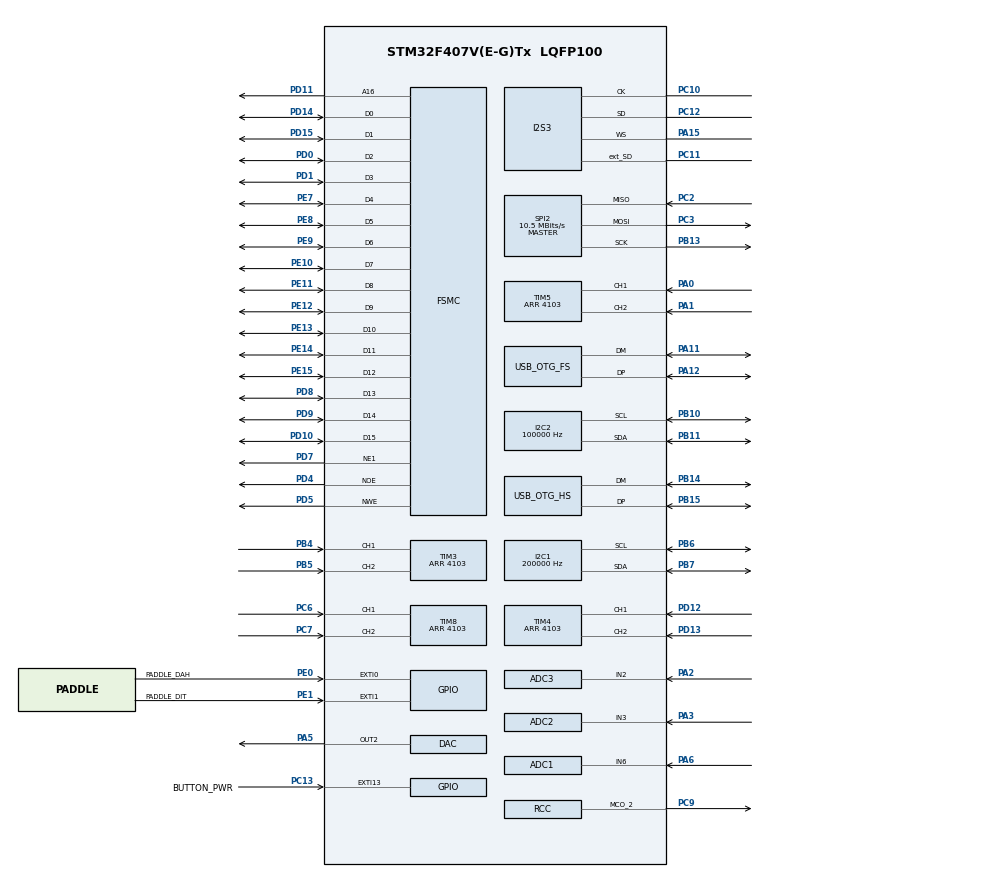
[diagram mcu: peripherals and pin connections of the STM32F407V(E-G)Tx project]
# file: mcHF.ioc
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ADC1.Channel-0\#ChannelRegularConversion=ADC_CHANNEL_6
ADC1.ClockPrescaler=ADC_CLOCK_SYNC_PCLK_DIV8
ADC1.ContinuousConvMode=ENABLE
ADC1.EOCSelection=ADC_EOC_SEQ_CONV
ADC1.NbrOfConversionFlag=1
ADC1.Rank-0\#ChannelRegularConversion=1
ADC1.SamplingTime-0\#ChannelRegularConversion=ADC_SAMPLETIME_3CYCLES
ADC1.master=1
ADC2.Channel-5\#ChannelRegularConversion=ADC_CHANNEL_3
ADC2.ClockPrescaler=ADC_CLOCK_SYNC_PCLK_DIV8
ADC2.ContinuousConvMode=ENABLE
ADC2.EOCSelection=ADC_EOC_SEQ_CONV
ADC2.NbrOfConversionFlag=1
ADC2.Rank-5\#ChannelRegularConversion=1
ADC2.SamplingTime-5\#ChannelRegularConversion=ADC_SAMPLETIME_3CYCLES
ADC3.Channel-5\#ChannelRegularConversion=ADC_CHANNEL_2
ADC3.ClockPrescaler=ADC_CLOCK_SYNC_PCLK_DIV8
ADC3.ContinuousConvMode=ENABLE
ADC3.EOCSelection=ADC_EOC_SEQ_CONV
ADC3.NbrOfConversionFlag=1
ADC3.Rank-5\#ChannelRegularConversion=1
ADC3.SamplingTime-5\#ChannelRegularConversion=ADC_SAMPLETIME_3CYCLES
Dma.I2S3_EXT_RX.2.Direction=DMA_PERIPH_TO_MEMORY
Dma.I2S3_EXT_RX.2.FIFOMode=DMA_FIFOMODE_ENABLE
Dma.I2S3_EXT_RX.2.FIFOThreshold=DMA_FIFO_THRESHOLD_FULL
Dma.I2S3_EXT_RX.2.Instance=DMA1_Stream2
Dma.I2S3_EXT_RX.2.MemBurst=DMA_MBURST_INC4
Dma.I2S3_EXT_RX.2.MemDataAlignment=DMA_MDATAALIGN_HALFWORD
Dma.I2S3_EXT_RX.2.MemInc=DMA_MINC_ENABLE
Dma.I2S3_EXT_RX.2.Mode=DMA_CIRCULAR
Dma.I2S3_EXT_RX.2.PeriphBurst=DMA_PBURST_SINGLE
Dma.I2S3_EXT_RX.2.PeriphDataAlignment=DMA_PDATAALIGN_HALFWORD
Dma.I2S3_EXT_RX.2.PeriphInc=DMA_PINC_DISABLE
Dma.I2S3_EXT_RX.2.Priority=DMA_PRIORITY_HIGH
Dma.Request0=SPI2_TX
Dma.Request1=SPI3_TX
Dma.Request2=I2S3_EXT_RX
Dma.SPI2_TX.0.Direction=DMA_MEMORY_TO_PERIPH
Dma.SPI2_TX.0.FIFOMode=DMA_FIFOMODE_DISABLE
Dma.SPI2_TX.0.Instance=DMA1_Stream4
Dma.SPI2_TX.0.MemDataAlignment=DMA_MDATAALIGN_BYTE
Dma.SPI2_TX.0.MemInc=DMA_MINC_ENABLE
Dma.SPI2_TX.0.Mode=DMA_NORMAL
Dma.SPI2_TX.0.PeriphDataAlignment=DMA_PDATAALIGN_BYTE
Dma.SPI2_TX.0.PeriphInc=DMA_PINC_DISABLE
Dma.SPI2_TX.0.Priority=DMA_PRIORITY_LOW
Dma.SPI3_TX.1.Direction=DMA_MEMORY_TO_PERIPH
Dma.SPI3_TX.1.FIFOMode=DMA_FIFOMODE_ENABLE
Dma.SPI3_TX.1.FIFOThreshold=DMA_FIFO_THRESHOLD_FULL
Dma.SPI3_TX.1.Instance=DMA1_Stream5
Dma.SPI3_TX.1.MemBurst=DMA_MBURST_SINGLE
Dma.SPI3_TX.1.MemDataAlignment=DMA_MDATAALIGN_HALFWORD
Dma.SPI3_TX.1.MemInc=DMA_MINC_ENABLE
Dma.SPI3_TX.1.Mode=DMA_CIRCULAR
Dma.SPI3_TX.1.PeriphBurst=DMA_PBURST_SINGLE
Dma.SPI3_TX.1.PeriphDataAlignment=DMA_PDATAALIGN_HALFWORD
Dma.SPI3_TX.1.PeriphInc=DMA_PINC_DISABLE
Dma.SPI3_TX.1.Priority=DMA_PRIORITY_HIGH
FSMC.AddressSetupTime1=6
FSMC.BusTurnAroundDuration1=0
FSMC.DataSetupTime1=15
I2C1.ClockSpeed=200000
I2C1.DutyCycle=I2C_DUTYCYCLE_16_9
I2C1.I2C_Mode=I2C_Fast
I2C1.OwnAddress=0x33
I2C2.ClockSpeed=100000
I2C2.DutyCycle=I2C_DUTYCYCLE_16_9
I2C2.I2C_Mode=I2C_Fast
I2C2.OwnAddress=0x33
I2S3.AudioFreq=I2S_AUDIOFREQ_96K
I2S3.ErrorAudioFreq=0.0 %
I2S3.FullDuplexMode=I2S_FULLDUPLEXMODE_ENABLE
I2S3.Instance=SPI$Index
I2S3.RealAudioFreq=96.0 KHz
I2S3.VirtualMode=I2S_MODE_MASTER
Mcu.Family=STM32F4
Mcu.Name=STM32F407V(E-G)Tx
Mcu.Package=LQFP100
NVIC.DMA1_Stream2_IRQn=true\:2\:0\:true\:false\:true\:true
NVIC.DMA1_Stream4_IRQn=true\:14\:0\:true\:false\:true\:true
NVIC.DMA1_Stream5_IRQn=true\:14\:0\:true\:false\:true\:true
NVIC.EXTI0_IRQn=true\:14\:0\:true\:false\:true\:true
NVIC.EXTI15_10_IRQn=true\:14\:0\:true\:false\:true\:true
NVIC.EXTI1_IRQn=true\:14\:0\:true\:false\:true\:true
NVIC.OTG_FS_IRQn=true\:1\:0\:true\:false\:true\:true
NVIC.OTG_HS_IRQn=true\:14\:0\:true\:false\:true\:true
NVIC.PriorityGroup=NVIC_PRIORITYGROUP_4
PA0-WKUP.GPIO_PuPd=GPIO_PULLUP
PA0-WKUP.Signal=S_TIM5_CH1
PA1.GPIO_PuPd=GPIO_PULLUP
PA1.Signal=S_TIM5_CH2
PA11.Mode=Device_Only
PA11.Signal=USB_OTG_FS_DM
PA12.Mode=Device_Only
PA12.Signal=USB_OTG_FS_DP
PA13.Mode=Serial_Wire
PA13.Signal=SYS_JTMS-SWDIO
PA14.Mode=Serial_Wire
PA14.Signal=SYS_JTCK-SWCLK
PA15.Mode=Full_Duplex_Master
PA15.Signal=I2S3_WS
PA2.Signal=ADCx_IN2
PA3.Signal=ADCx_IN3
PA5.Signal=COMP_DAC2_group
PA6.Signal=ADCx_IN6
PB10.Mode=I2C
PB10.Signal=I2C2_SCL
PB11.Mode=I2C
PB11.Signal=I2C2_SDA
PB13.Mode=Full_Duplex_Master
PB13.Signal=SPI2_SCK
PB14.Mode=Host_FS
PB14.Signal=USB_OTG_HS_DM
PB15.Mode=Host_FS
PB15.Signal=USB_OTG_HS_DP
PB4.GPIO_PuPd=GPIO_PULLUP
PB4.Signal=S_TIM3_CH1
PB5.GPIO_PuPd=GPIO_PULLUP
PB5.Signal=S_TIM3_CH2
PB6.Mode=I2C
PB6.Signal=I2C1_SCL
PB7.Mode=I2C
PB7.Signal=I2C1_SDA
PC10.Mode=Full_Duplex_Master
PC10.Signal=I2S3_CK
PC11.Mode=Full_Duplex_Master
PC11.Signal=I2S3_ext_SD
PC12.Mode=Full_Duplex_Master
PC12.Signal=I2S3_SD
PC13-ANTI_TAMP.GPIO_Label=BUTTON_PWR
PC13-ANTI_TAMP.GPIO_ModeDefaultEXTI=GPIO_MODE_IT_FALLING
PC13-ANTI_TAMP.GPIO_PuPd=GPIO_PULLUP
PC13-ANTI_TAMP.Signal=GPXTI13
PC14-OSC32_IN.Mode=LSE-External-Oscillator
PC14-OSC32_IN.Signal=RCC_OSC32_IN
PC15-OSC32_OUT.Mode=LSE-External-Oscillator
PC15-OSC32_OUT.Signal=RCC_OSC32_OUT
PC2.Mode=Full_Duplex_Master
PC2.Signal=SPI2_MISO
PC3.Mode=Full_Duplex_Master
PC3.Signal=SPI2_MOSI
PC6.GPIO_PuPd=GPIO_PULLUP
PC6.Signal=S_TIM8_CH1
PC7.GPIO_PuPd=GPIO_PULLUP
PC7.Signal=S_TIM8_CH2
PC9.Mode=Clock-out-2
PC9.Signal=RCC_MCO_2
PD0.Mode=16b-d1
PD0.Signal=FSMC_D2
PD1.Mode=16b-d1
PD1.Signal=FSMC_D3
PD10.Mode=16b-d1
PD10.Signal=FSMC_D15
PD11.Mode=A16_1
PD11.Signal=FSMC_A16
PD12.GPIO_PuPd=GPIO_PULLUP
PD12.Signal=S_TIM4_CH1
PD13.GPIO_PuPd=GPIO_PULLUP
PD13.Signal=S_TIM4_CH2
PD14.Mode=16b-d1
PD14.Signal=FSMC_D0
PD15.Mode=16b-d1
PD15.Signal=FSMC_D1
PD4.Mode=Lcd1
PD4.Signal=FSMC_NOE
PD5.Mode=Lcd1
PD5.Signal=FSMC_NWE
PD7.Mode=NorPsramChipSelect1_1
PD7.Signal=FSMC_NE1
PD8.Mode=16b-d1
PD8.Signal=FSMC_D13
PD9.Mode=16b-d1
PD9.Signal=FSMC_D14
PE0.GPIO_Label=PADDLE_DAH
PE0.GPIO_ModeDefaultEXTI=GPIO_MODE_IT_FALLING
PE0.GPIO_PuPd=GPIO_PULLUP
PE0.Signal=GPXTI0
PE1.GPIO_Label=PADDLE_DIT
PE1.GPIO_ModeDefaultEXTI=GPIO_MODE_IT_FALLING
PE1.GPIO_PuPd=GPIO_PULLUP
PE1.Signal=GPXTI1
PE10.Mode=16b-d1
PE10.Signal=FSMC_D7
PE11.Mode=16b-d1
PE11.Signal=FSMC_D8
PE12.Mode=16b-d1
PE12.Signal=FSMC_D9
PE13.Mode=16b-d1
PE13.Signal=FSMC_D10
PE14.Mode=16b-d1
PE14.Signal=FSMC_D11
PE15.Mode=16b-d1
PE15.Signal=FSMC_D12
PE7.Mode=16b-d1
PE7.Signal=FSMC_D4
PE8.Mode=16b-d1
PE8.Signal=FSMC_D5
PE9.Mode=16b-d1
PE9.Signal=FSMC_D6
PH0-OSC_IN.Mode=HSE-External-Oscillator
PH0-OSC_IN.Signal=RCC_OSC_IN
PH1-OSC_OUT.Mode=HSE-External-Oscillator
PH1-OSC_OUT.Signal=RCC_OSC_OUT
ProjectManager.HeapSize=0x200
ProjectManager.StackSize=0x400
ProjectManager.TargetToolchain=Other Toolchains (GPDSC)
RCC.48MHZClocksFreq_Value=48000000
RCC.AHBFreq_Value=168000000
RCC.APB1CLKDivider=RCC_HCLK_DIV4
RCC.APB1Freq_Value=42000000
RCC.APB1TimFreq_Value=84000000
RCC.APB2CLKDivider=RCC_HCLK_DIV2
RCC.APB2Freq_Value=84000000
RCC.APB2TimFreq_Value=168000000
RCC.CortexFreq_Value=168000000
RCC.HCLKFreq_Value=168000000
RCC.HSE_VALUE=16000000
RCC.HSI_VALUE=16000000
RCC.PLLI2SR=5
RCC.PLLM=10
RCC.PLLN=210
RCC.PLLQ=7
RCC.RCC_MCO2Source=RCC_MCO2SOURCE_PLLI2SCLK
RCC.RCC_MCODiv2=RCC_MCODIV_5
RCC.RCC_RTC_Clock_Source=RCC_RTCCLKSOURCE_LSE
RCC.RCC_RTC_Clock_SourceVirtual=RCC_RTCCLKSOURCE_LSE
RCC.SYSCLKFreq_VALUE=168000000
RCC.SYSCLKSource=RCC_SYSCLKSOURCE_PLLCLK
RCC.VCOOutputFreq_Value=336000000
SH.ADCx_IN2.0=ADC3_IN2,IN2
SH.ADCx_IN3.0=ADC2_IN3,IN3
SH.ADCx_IN6.0=ADC1_IN6,IN6
SH.COMP_DAC2_group.0=DAC_OUT2,DAC_OUT2
SH.S_TIM3_CH1.0=TIM3_CH1,Encoder_Interface
SH.S_TIM3_CH2.0=TIM3_CH2,Encoder_Interface
SH.S_TIM4_CH1.0=TIM4_CH1,Encoder_Interface
SH.S_TIM4_CH2.0=TIM4_CH2,Encoder_Interface
SH.S_TIM5_CH1.0=TIM5_CH1,Encoder_Interface
SH.S_TIM5_CH2.0=TIM5_CH2,Encoder_Interface
SH.S_TIM8_CH1.0=TIM8_CH1,Encoder_Interface
SH.S_TIM8_CH2.0=TIM8_CH2,Encoder_Interface
SPI2.BaudRatePrescaler=SPI_BAUDRATEPRESCALER_4
SPI2.CLKPhase=SPI_PHASE_2EDGE
SPI2.CLKPolarity=SPI_POLARITY_HIGH
SPI2.CalculateBaudRate=10.5 MBits/s
SPI2.Direction=SPI_DIRECTION_2LINES
SPI2.Mode=SPI_MODE_MASTER
SPI2.VirtualType=VM_MASTER
TIM3.EncoderMode=TIM_ENCODERMODE_TI12
TIM3.IC1Polarity=TIM_ICPOLARITY_FALLING
TIM3.IC2Polarity=TIM_ICPOLARITY_FALLING
TIM3.Period=4103
TIM4.EncoderMode=TIM_ENCODERMODE_TI12
TIM4.IC1Polarity=TIM_ICPOLARITY_FALLING
TIM4.IC2Polarity=TIM_ICPOLARITY_FALLING
TIM4.Period=4103
TIM5.EncoderMode=TIM_ENCODERMODE_TI12
TIM5.IC1Polarity=TIM_ICPOLARITY_FALLING
TIM5.IC2Polarity=TIM_ICPOLARITY_FALLING
TIM5.Period=4103
TIM8.EncoderMode=TIM_ENCODERMODE_TI12
TIM8.IC1Polarity=TIM_ICPOLARITY_FALLING
TIM8.IC2Polarity=TIM_ICPOLARITY_FALLING
TIM8.Period=4103
USB_DEVICE.CLASS_NAME_FS=AUDIO
USB_DEVICE.PID_AUDIO_FS=0x7740
USB_DEVICE.SERIALNUMBER_STRING_AUDIO_FS=00000000002A
USB_DEVICE.USBD_AUDIO_FREQ-AUDIO_FS=96000U                        // NIZ96
USB_DEVICE.USBD_MAX_NUM_INTERFACES-AUDIO_FS=5
USB_DEVICE.VirtualModeFS=Audio_FS
USB_HOST.USBH_HandleTypeDef-ALL_Classes_HS=hUsbHostHS
USB_HOST.VirtualModeHS=All_Classes
USB_OTG_FS.Sof_enable=ENABLE
USB_OTG_FS.VirtualMode=Device_Only
USB_OTG_FS.vbus_sensing_enable=DISABLE
USB_OTG_HS.VirtualMode-Host_FS=Host_FS
VP_FATFS_VS_Generic.Mode=User_defined
VP_RTC_VS_RTC_Activate.Mode=RTC_Enabled
VP_USB_DEVICE_VS_USB_DEVICE_AUDIO_FS.Mode=AUDIO_FS
VP_USB_HOST_VS_USB_HOST_ALL_CLASS_HS.Mode=ALL_Classes_HS
board=mcHF

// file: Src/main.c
/**
  ******************************************************************************
  * File Name          : main.c
  * Description        : Main program body
  ******************************************************************************
  *
  * Copyright (c) 2017 STMicroelectronics International N.V.
  * All rights reserved.
  *
  * Redistribution and use in source and binary forms, with or without
  * modification, are permitted, provided that the following conditions are met:
  *
  * 1. Redistribution of source code must retain the above copyright notice,
  *    this list of conditions and the following disclaimer.
  * 2. Redistributions in binary form must reproduce the above copyright notice,
  *    this list of conditions and the following disclaimer in the documentation
  *    and/or other materials provided with the distribution.
  * 3. Neither the name of STMicroelectronics nor the names of other
  *    contributors to this software may be used to endorse or promote products
  *    derived from this software without specific written permission.
  * 4. This software, including modifications and/or derivative works of this
  *    software, must execute solely and exclusively on microcontroller or
  *    microprocessor devices manufactured by or for STMicroelectronics.
  * 5. Redistribution and use of this software other than as permitted under
  *    this license is void and will automatically terminate your rights under
  *    this license.
  *
  * THIS SOFTWARE IS PROVIDED BY STMICROELECTRONICS AND CONTRIBUTORS "AS IS"
  * AND ANY EXPRESS, IMPLIED OR STATUTORY WARRANTIES, INCLUDING, BUT NOT
  * LIMITED TO, THE IMPLIED WARRANTIES OF MERCHANTABILITY, FITNESS FOR A
  * PARTICULAR PURPOSE AND NON-INFRINGEMENT OF THIRD PARTY INTELLECTUAL PROPERTY
  * RIGHTS ARE DISCLAIMED TO THE FULLEST EXTENT PERMITTED BY LAW. IN NO EVENT
  * SHALL STMICROELECTRONICS OR CONTRIBUTORS BE LIABLE FOR ANY DIRECT, INDIRECT,
  * INCIDENTAL, SPECIAL, EXEMPLARY, OR CONSEQUENTIAL DAMAGES (INCLUDING, BUT NOT
  * LIMITED TO, PROCUREMENT OF SUBSTITUTE GOODS OR SERVICES; LOSS OF USE, DATA,
  * OR PROFITS; OR BUSINESS INTERRUPTION) HOWEVER CAUSED AND ON ANY THEORY OF
  * LIABILITY, WHETHER IN CONTRACT, STRICT LIABILITY, OR TORT (INCLUDING
  * NEGLIGENCE OR OTHERWISE) ARISING IN ANY WAY OUT OF THE USE OF THIS SOFTWARE,
  * EVEN IF ADVISED OF THE POSSIBILITY OF SUCH DAMAGE.
  *
  ******************************************************************************
  */
#include "main.h"
#include "stm32f4xx_hal.h"
#include "adc.h"
#include "dac.h"
#include "dma.h"
#include "fatfs.h"
#include "i2c.h"
#include "i2s.h"
#include "rtc.h"
#include "spi.h"
#include "tim.h"
#include "usb_device.h"
#include "usb_host.h"
#include "gpio.h"
#include "fsmc.h"

/* USER CODE BEGIN PV */
/* Private variables ---------------------------------------------------------*/

/* USER CODE END PV */

void SystemClock_Config(void);
void Error_Handler(void);

/* USER CODE BEGIN PFP */
/* Private function prototypes -----------------------------------------------*/

/* USER CODE END PFP */

/* USER CODE BEGIN 0 */
#ifdef BOOTLOADER_BUILD
void MX_USB_HOST_Process(void);
#include "bootloader/bootloader_main.h"
#else

#include "uhsdr_main.h"

#endif
/* USER CODE END 0 */

int main(void)
{

  /* USER CODE BEGIN 1 */
#ifdef BOOTLOADER_BUILD
  mchfBl_CheckAndGoForDfuBoot();
  //  we need to do this as early as possible
#endif
  /* USER CODE END 1 */

  /* MCU Configuration----------------------------------------------------------*/

  /* Reset of all peripherals, Initializes the Flash interface and the Systick. */
  HAL_Init();

  HAL_RCC_DeInit();

  /* Configure the system clock */
  SystemClock_Config();

  /* Initialize all configured peripherals */

#ifdef BOOTLOADER_BUILD
  bootloader_main();
#else
  MX_GPIO_Init();
  MX_DMA_Init();
  MX_ADC1_Init();
  MX_ADC2_Init();
  MX_ADC3_Init();
  MX_DAC_Init();
  MX_I2C1_Init();
  MX_I2C2_Init();
  MX_I2S3_Init();
  MX_RTC_Init();
  MX_SPI2_Init();
  MX_TIM3_Init();
  MX_TIM5_Init();
  MX_TIM8_Init();
  MX_USB_DEVICE_Init();
#endif
#if defined(USE_USBHOST) || defined(BOOTLOADER_BUILD)
  MX_USB_HOST_Init();
#if defined(USE_USBDRIVE) || defined(BOOTLOADER_BUILD)
  MX_FATFS_Init();
#endif  // MX_FSMC_Init();
#endif
#ifndef BOOTLOADER_BUILD
  MX_TIM4_Init();
#endif
  /* USER CODE BEGIN 2 */
#ifndef BOOTLOADER_BUILD
   mchfMain();
  /* USER CODE END 2 */

  /* Infinite loop */
  /* USER CODE BEGIN WHILE */
#else
  while (1)
  {
  /* USER CODE END WHILE */
    MX_USB_HOST_Process();

    /* USER CODE BEGIN 3 */
    BL_Application();

  }
#endif
  /* USER CODE END 3 */

}

/** System Clock Configuration
*/
void   SystemClock_Config( void )
{

  RCC_OscInitTypeDef        RCC_OscInitStruct;
  RCC_ClkInitTypeDef        RCC_ClkInitStruct;
  RCC_PeriphCLKInitTypeDef  PeriphClkInitStruct;

    /**Configure the main internal regulator output voltage
    */
  __HAL_RCC_PWR_CLK_ENABLE();

  __HAL_PWR_VOLTAGESCALING_CONFIG( PWR_REGULATOR_VOLTAGE_SCALE1 );

    /**Initializes the CPU, AHB and APB busses clocks
    */
  RCC_OscInitStruct.OscillatorType = RCC_OSCILLATORTYPE_HSE;
  RCC_OscInitStruct.HSEState       = RCC_HSE_ON;
  RCC_OscInitStruct.LSEState       = RCC_LSE_ON;
  RCC_OscInitStruct.PLL.PLLState   = RCC_PLL_ON;
  RCC_OscInitStruct.PLL.PLLSource  = RCC_PLLSOURCE_HSE;

  // 16Mhz Quartz divise par 10 = 1.6Mhz, multiplié par 210 = 336Mhz , divise par 2 = 168Mhz Coeur  , 336Mhz/7 = 48Mhz pour USB
  // Overclocking
  // 168Mhz : Quartz=16Mhz , PLLM=10 , PLLN = 210 , PLLP = DIV2, PLLQ = 7 (->USB=48.00Mhz) , PLLI2SN=192,  PLLI2SR=5; RCC_MCODIV_5
  // 180Mhz : Quartz=16Mhz , PLLM=10 , PLLN = 225 , PLLP = DIV2, PLLQ = 7 (->USB=51.43Mhz) , PLLI2SN=192,  PLLI2SR=5; RCC_MCODIV_5 // USB ne marche pas, non reconnaissable
  // 192Mhz : Quartz=16Mhz , PLLM=10 , PLLN = 240 , PLLP = DIV2, PLLQ = 8 (->USB=48.00Mhz) , PLLI2SN=192,  PLLI2SR=5; RCC_MCODIV_5
  // 216Mhz : Quartz=16Mhz , PLLM=10 , PLLN = 270 , PLLP = DIV2, PLLQ = 9 (->USB=48.00Mhz) , PLLI2SN=192,  PLLI2SR=5; RCC_MCODIV_5

  RCC_OscInitStruct.PLL.PLLM       = 10;             // (2..63) Diviseur
  RCC_OscInitStruct.PLL.PLLN       = 210;            // (50..432) Multiplicat // Attention PLL de 100Mhz min a 432Mhz max
  RCC_OscInitStruct.PLL.PLLP       = RCC_PLLP_DIV2;  // DIV2, DIV4 , DIV6 ou DIV8 c'est tout ce qu'il ya
  RCC_OscInitStruct.PLL.PLLQ       = 7;              // (2..15) pour 48Mhz USB ou tres proche de 48Mhz
                                                     // Pour notre radio RS928 il faut quelle soit exactement 48Mhz, si non le PC ne reconnait pas le port USB, ne marche pas

  if ( HAL_RCC_OscConfig( &RCC_OscInitStruct ) != HAL_OK)
  {
    Error_Handler();
  }

    /**Initializes the CPU, AHB and APB busses clocks
    */
  RCC_ClkInitStruct.ClockType      =   RCC_CLOCKTYPE_HCLK  | RCC_CLOCKTYPE_SYSCLK
                                     | RCC_CLOCKTYPE_PCLK1 | RCC_CLOCKTYPE_PCLK2;
  RCC_ClkInitStruct.SYSCLKSource   = RCC_SYSCLKSOURCE_PLLCLK;
  RCC_ClkInitStruct.AHBCLKDivider  = RCC_SYSCLK_DIV1;
  RCC_ClkInitStruct.APB1CLKDivider = RCC_HCLK_DIV4;
  RCC_ClkInitStruct.APB2CLKDivider = RCC_HCLK_DIV2;

  if ( HAL_RCC_ClockConfig( &RCC_ClkInitStruct, FLASH_LATENCY_5 ) != HAL_OK )
  {
       Error_Handler();
  }

  // NB: Le PLL du I2S tire sa reference directement du quartz 16Mhz divisé par le PLLM  (le 1er diviseur du core)
  // il semble qu'il y a une division de plus par 10 avant d'appliquer ces multiplicateur/diviseur
  // le codec WM8731 nécessite MCLK = 12.288 Mhz quelque soit la FS sous multiple de 96Khz

  // I2S_freq = (( Quartz_freq /PLLM) * PLLI2SN ) /PLLI2SR = 61.44 Mhz // PLLM semble celui du processeur
  // Clock I2S = [ 16Mhz / PLLM(10) * PLLI2SN(192) / PLLI2SR(5) ] = 61.44 Mhz

  PeriphClkInitStruct.PeriphClockSelection = RCC_PERIPHCLK_I2S | RCC_PERIPHCLK_RTC;
  PeriphClkInitStruct.PLLI2S.PLLI2SN       = 192;   // de 50 min à 432 max, Multiplicateur du (Quartz/PLLM)
  PeriphClkInitStruct.PLLI2S.PLLI2SR       = 5;     // de 2 min à 7 max, Diviseur final pour avoir Freq I2S
  PeriphClkInitStruct.RTCClockSelection    = RCC_RTCCLKSOURCE_LSE;   // RTC=32.768 Khz
  if (HAL_RCCEx_PeriphCLKConfig(&PeriphClkInitStruct) != HAL_OK)
  {
    Error_Handler();
  }

  	// La Division par 5 du clock I2S (61.44Mhz) pour obtenir le I2S_MSK  (12.288 Mhz) au pin PC10 nécessaire pour commander le codec WM8731S
	// On peut utiliser les diviseurs :  RCC_MCODIV_1,  RCC_MCODIV_2,  RCC_MCODIV_3,  RCC_MCODIV_4,  RCC_MCODIV_5
	// on choisit aussi en meme temps la source du MCO PLLI2SCLK (61.44 Mhz)

  HAL_RCC_MCOConfig( RCC_MCO2, RCC_MCO2SOURCE_PLLI2SCLK, RCC_MCODIV_5 );

    /**Configure the Systick interrupt time
    */
  HAL_SYSTICK_Config( HAL_RCC_GetHCLKFreq()/1000 );  // reglage du tick a chaque 1ms quelque soit la frequence du systeme déja tabli

    /**Configure the Systick
    */
  HAL_SYSTICK_CLKSourceConfig( SYSTICK_CLKSOURCE_HCLK );

  /* SysTick_IRQn interrupt configuration */
  HAL_NVIC_SetPriority( SysTick_IRQn, 0, 0 );
}

void Error_Handler( void )
{
  while(1)
  {
  }
}

/************************ (C) COPYRIGHT STMicroelectronics *****END OF FILE****/
